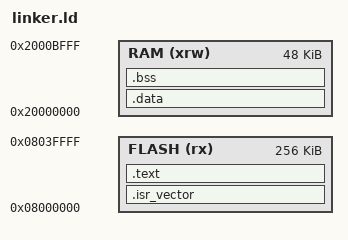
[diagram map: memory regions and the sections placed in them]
ENTRY(Reset_Handler)

MEMORY
{
  FLASH (rx) : ORIGIN = 0x08000000, LENGTH = 256K
  RAM (xrw)  : ORIGIN = 0x20000000, LENGTH = 48K
}

_estack = ORIGIN(RAM) + LENGTH(RAM);

SECTIONS
{
  .isr_vector :
  {
    KEEP(*(.isr_vector))
  } > FLASH

  .text :
  {
    *(.text*)
    *(.rodata*)
  } > FLASH

  .data : AT (ADDR(.text) + SIZEOF(.text))
  {
    _sdata = .;
    *(.data*)
    _edata = .;
  } > RAM

  .bss :
  {
    _sbss = .;
    *(.bss*)
    *(COMMON)
    _ebss = .;
  } > RAM

  .sidata = LOADADDR(.data);
  _sidata = LOADADDR(.data);
}
